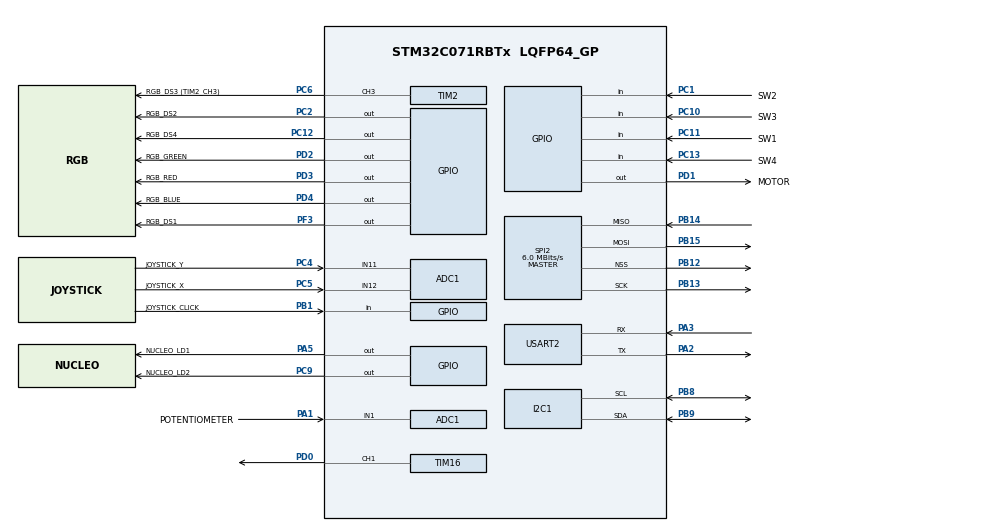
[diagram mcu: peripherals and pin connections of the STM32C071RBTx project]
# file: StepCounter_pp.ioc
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ADC1.SelectedChannel=ADC_CHANNEL_1|ADC_CHANNEL_11|ADC_CHANNEL_12
ADC1.master=1
Dma.ADC1.0.Direction=DMA_PERIPH_TO_MEMORY
Dma.ADC1.0.EventEnable=DISABLE
Dma.ADC1.0.Instance=DMA1_Channel1
Dma.ADC1.0.MemDataAlignment=DMA_MDATAALIGN_HALFWORD
Dma.ADC1.0.MemInc=DMA_MINC_ENABLE
Dma.ADC1.0.Mode=DMA_NORMAL
Dma.ADC1.0.PeriphDataAlignment=DMA_PDATAALIGN_HALFWORD
Dma.ADC1.0.PeriphInc=DMA_PINC_DISABLE
Dma.ADC1.0.Polarity=HAL_DMAMUX_REQ_GEN_RISING
Dma.ADC1.0.Priority=DMA_PRIORITY_LOW
Dma.ADC1.0.RequestNumber=1
Dma.ADC1.0.SignalID=NONE
Dma.ADC1.0.SyncEnable=DISABLE
Dma.ADC1.0.SyncPolarity=HAL_DMAMUX_SYNC_NO_EVENT
Dma.ADC1.0.SyncRequestNumber=1
Dma.ADC1.0.SyncSignalID=NONE
Dma.I2C1_TX.1.Direction=DMA_MEMORY_TO_PERIPH
Dma.I2C1_TX.1.EventEnable=DISABLE
Dma.I2C1_TX.1.Instance=DMA1_Channel2
Dma.I2C1_TX.1.MemDataAlignment=DMA_MDATAALIGN_BYTE
Dma.I2C1_TX.1.MemInc=DMA_MINC_ENABLE
Dma.I2C1_TX.1.Mode=DMA_NORMAL
Dma.I2C1_TX.1.PeriphDataAlignment=DMA_PDATAALIGN_BYTE
Dma.I2C1_TX.1.PeriphInc=DMA_PINC_DISABLE
Dma.I2C1_TX.1.Polarity=HAL_DMAMUX_REQ_GEN_RISING
Dma.I2C1_TX.1.Priority=DMA_PRIORITY_LOW
Dma.I2C1_TX.1.RequestNumber=1
Dma.I2C1_TX.1.SignalID=NONE
Dma.I2C1_TX.1.SyncEnable=DISABLE
Dma.I2C1_TX.1.SyncPolarity=HAL_DMAMUX_SYNC_NO_EVENT
Dma.I2C1_TX.1.SyncRequestNumber=1
Dma.I2C1_TX.1.SyncSignalID=NONE
Dma.Request0=ADC1
Dma.Request1=I2C1_TX
I2C1.Timing=0x00402D41
Mcu.Family=STM32C0
Mcu.Name=STM32C071RBTx
Mcu.Package=LQFP64_GP
NVIC.DMA1_Channel1_IRQn=true\:0\:0\:false\:false\:true\:false\:true\:true
NVIC.DMA1_Channel2_3_IRQn=true\:0\:0\:false\:false\:true\:false\:true\:true
NVIC.I2C1_IRQn=true\:0\:0\:false\:false\:true\:true\:true\:true
PA1.GPIO_Label=POTENTIOMETER
PA1.Mode=IN1
PA1.Signal=ADC1_IN1
PA13.Mode=Serial_Wire
PA13.Signal=DEBUG_SWDIO
PA14-BOOT0.Mode=Serial_Wire
PA14-BOOT0.Signal=DEBUG_SWCLK
PA2.Mode=Asynchronous
PA2.Signal=USART2_TX
PA3.Mode=Asynchronous
PA3.Signal=USART2_RX
PA5.GPIO_Label=NUCLEO_LD1
PA5.Signal=GPIO_Output
PB1.GPIO_Label=JOYSTICK_CLICK
PB1.GPIO_PuPd=GPIO_PULLDOWN
PB1.Signal=GPIO_Input
PB12.Mode=NSS_Signal_Hard_Output
PB12.Signal=SPI2_NSS
PB13.Mode=Full_Duplex_Master
PB13.Signal=SPI2_SCK
PB14.Mode=Full_Duplex_Master
PB14.Signal=SPI2_MISO
PB15.Mode=Full_Duplex_Master
PB15.Signal=SPI2_MOSI
PB8.Mode=I2C
PB8.Signal=I2C1_SCL
PB9.Mode=I2C
PB9.Signal=I2C1_SDA
PC1.GPIO_Label=SW2
PC1.GPIO_PuPd=GPIO_PULLDOWN
PC1.Signal=GPIO_Input
PC10.GPIO_Label=SW3
PC10.GPIO_PuPd=GPIO_PULLDOWN
PC10.Signal=GPIO_Input
PC11.GPIO_Label=SW1
PC11.GPIO_PuPd=GPIO_PULLDOWN
PC11.Signal=GPIO_Input
PC12.GPIO_Label=RGB_DS4
PC12.PinState=GPIO_PIN_SET
PC12.Signal=GPIO_Output
PC13.GPIO_Label=SW4
PC13.GPIO_PuPd=GPIO_PULLUP
PC13.Signal=GPIO_Input
PC2.GPIO_Label=RGB_DS2
PC2.PinState=GPIO_PIN_SET
PC2.Signal=GPIO_Output
PC4.GPIO_Label=JOYSTICK_Y
PC4.Mode=IN11
PC4.Signal=ADC1_IN11
PC5.GPIO_Label=JOYSTICK_X
PC5.Mode=IN12
PC5.Signal=ADC1_IN12
PC6.GPIO_Label=RGB_DS3 (TIM2_CH3)
PC6.Signal=S_TIM2_CH3
PC9.GPIO_Label=NUCLEO_LD2
PC9.Signal=GPIO_Output
PD0.Signal=S_TIM16_CH1
PD1.GPIO_Label=MOTOR
PD1.Signal=GPIO_Output
PD2.GPIO_Label=RGB_GREEN
PD2.Signal=GPIO_Output
PD3.GPIO_Label=RGB_RED
PD3.Signal=GPIO_Output
PD4.GPIO_Label=RGB_BLUE
PD4.Signal=GPIO_Output
PF3.GPIO_Label=RGB_DS1
PF3.PinState=GPIO_PIN_SET
PF3.Signal=GPIO_Output
ProjectManager.HeapSize=0x200
ProjectManager.StackSize=0x400
ProjectManager.TargetToolchain=STM32CubeIDE
RCC.ADCFreq_Value=12000000
RCC.AHBFreq_Value=12000000
RCC.CortexFreq_Value=12000000
RCC.EXTERNAL_CLOCK_VALUE=12288000
RCC.HCLKFreq_Value=12000000
RCC.HSE_VALUE=8000000
RCC.HSI48_VALUE=48000000
RCC.HSI_VALUE=48000000
RCC.LSE_VALUE=32768
RCC.SYSCLKFreq_VALUE=12000000
SH.S_TIM16_CH1.0=TIM16_CH1,PWM Generation1 CH1
SH.S_TIM2_CH3.0=TIM2_CH3,PWM Generation3 CH3
SPI2.CalculateBaudRate=6.0 MBits/s
SPI2.DataSize=SPI_DATASIZE_16BIT
SPI2.Direction=SPI_DIRECTION_2LINES
SPI2.Mode=SPI_MODE_MASTER
SPI2.VirtualNSS=VM_NSSHARD
SPI2.VirtualType=VM_MASTER
TIM16.Channel=TIM_CHANNEL_1
TIM16.Pulse=0
TIM2.Channel-PWM\ Generation3\ CH3=TIM_CHANNEL_3
TIM2.OCPolarity_3=TIM_OCPOLARITY_LOW
TIM2.Period=100000
USART2.VirtualMode-Asynchronous=VM_ASYNC
VP_TIM16_VS_ClockSourceINT.Mode=Enable_Timer
board=custom

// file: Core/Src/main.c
/* USER CODE BEGIN Header */
/**
  ******************************************************************************
  * @file           : main.c
  * @brief          : Main program body
  ******************************************************************************
  * @attention
  *
  * Copyright (c) 2025 STMicroelectronics.
  * All rights reserved.
  *
  * This software is licensed under terms that can be found in the LICENSE file
  * in the root directory of this software component.
  * If no LICENSE file comes with this software, it is provided AS-IS.
  *
  ******************************************************************************
  */
/* USER CODE END Header */
#include "main.h"
#include "adc.h"
#include "dma.h"
#include "i2c.h"
#include "spi.h"
#include "tim.h"
#include "usart.h"
#include "gpio.h"

/* USER CODE BEGIN Includes */
#include "app.h"
/* USER CODE END Includes */

void SystemClock_Config(void);

int main(void)
{

  /* MCU Configuration--------------------------------------------------------*/

  /* Reset of all peripherals, Initializes the Flash interface and the Systick. */
  HAL_Init();

  /* Configure the system clock */
  SystemClock_Config();

  /* Initialize all configured peripherals */
  MX_GPIO_Init();
  MX_DMA_Init();
  MX_ADC1_Init();
  MX_I2C1_Init();
  MX_USART2_UART_Init();
  MX_TIM2_Init();
  MX_TIM16_Init();
  MX_SPI2_Init();
  /* USER CODE BEGIN 2 */
  appSetup();
  /* USER CODE END 2 */

  /* Infinite loop */
  /* USER CODE BEGIN WHILE */
  while (1)
  {
	appMain();
    /* USER CODE END WHILE */

  }
}

void SystemClock_Config(void)
{
  RCC_OscInitTypeDef RCC_OscInitStruct = {0};
  RCC_ClkInitTypeDef RCC_ClkInitStruct = {0};

  /** Initializes the RCC Oscillators according to the specified parameters
  * in the RCC_OscInitTypeDef structure.
  */
  RCC_OscInitStruct.OscillatorType = RCC_OSCILLATORTYPE_HSI;
  RCC_OscInitStruct.HSIState = RCC_HSI_ON;
  RCC_OscInitStruct.HSIDiv = RCC_HSI_DIV4;
  RCC_OscInitStruct.HSICalibrationValue = RCC_HSICALIBRATION_DEFAULT;
  if (HAL_RCC_OscConfig(&RCC_OscInitStruct) != HAL_OK)
  {
    Error_Handler();
  }

  /** Initializes the CPU, AHB and APB buses clocks
  */
  RCC_ClkInitStruct.ClockType = RCC_CLOCKTYPE_HCLK|RCC_CLOCKTYPE_SYSCLK
                              |RCC_CLOCKTYPE_PCLK1;
  RCC_ClkInitStruct.SYSCLKSource = RCC_SYSCLKSOURCE_HSI;
  RCC_ClkInitStruct.SYSCLKDivider = RCC_SYSCLK_DIV1;
  RCC_ClkInitStruct.AHBCLKDivider = RCC_HCLK_DIV1;
  RCC_ClkInitStruct.APB1CLKDivider = RCC_APB1_DIV1;

  if (HAL_RCC_ClockConfig(&RCC_ClkInitStruct, FLASH_LATENCY_0) != HAL_OK)
  {
    Error_Handler();
  }
}

void Error_Handler(void)
{
  __disable_irq();
  while (1)
  {
  }
}
